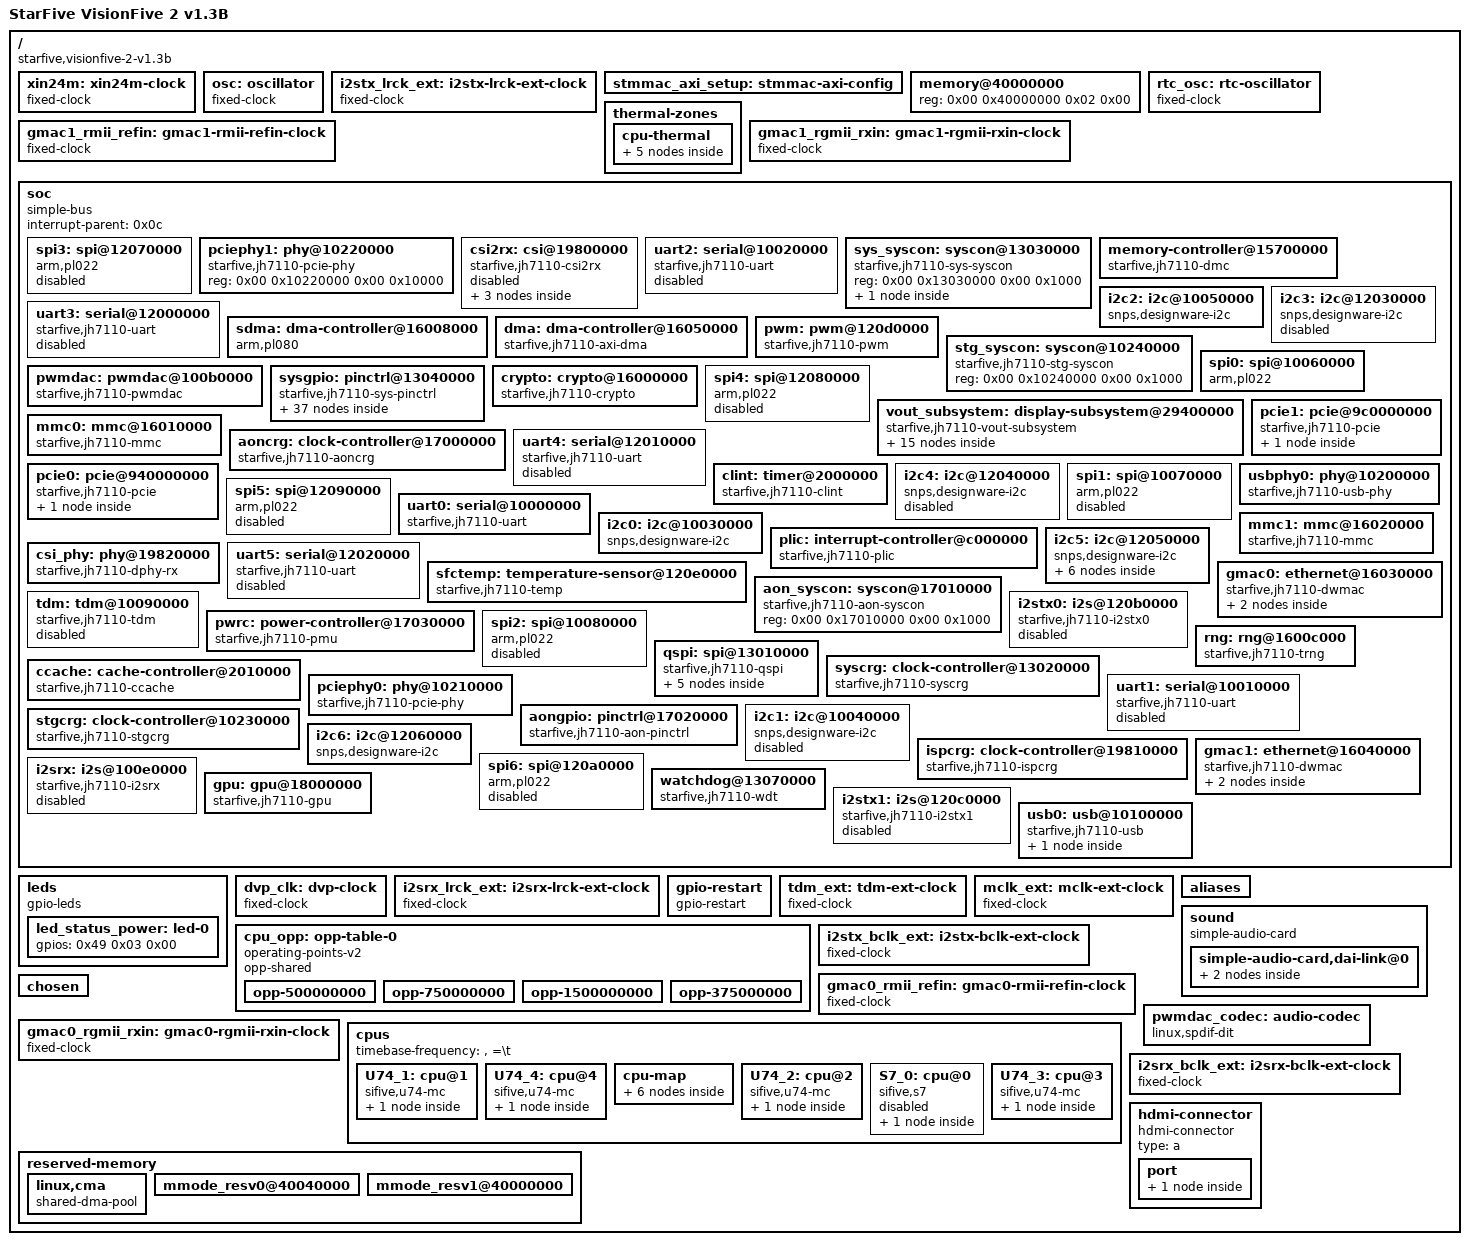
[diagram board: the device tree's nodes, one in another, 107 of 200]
/dts-v1/;

/ {
	#address-cells = <0x02>;
	model = "StarFive VisionFive 2 v1.3B";
	serial-number = "VF7110B1-2318-D008E000-18004700";
	#size-cells = <0x02>;
	compatible = "starfive,visionfive-2-v1.3b", "starfive,jh7110";

	xin24m: xin24m-clock {
		clock-output-names = "xin24m";
		#clock-cells = <0x00>;
		clock-frequency = <0x16e3600>;
		compatible = "fixed-clock";
		phandle = <0x42>;
	};

	osc: oscillator {
		clock-output-names = "osc";
		#clock-cells = <0x00>;
		clock-frequency = <0x16e3600>;
		compatible = "fixed-clock";
		bootph-pre-ram;
		phandle = <0x20>;
	};

	i2stx_lrck_ext: i2stx-lrck-ext-clock {
		clock-output-names = "i2stx_lrck_ext";
		#clock-cells = <0x00>;
		clock-frequency = <0x2ee00>;
		compatible = "fixed-clock";
		phandle = <0x24>;
	};

	stmmac_axi_setup: stmmac-axi-config {
		snps,lpi_en;
		snps,wr_osr_lmt = <0x0f>;
		phandle = <0x30>;
		snps,blen = <0x100 0x80 0x40 0x20 0x00 0x00 0x00>;
		snps,rd_osr_lmt = <0x0f>;
	};

	memory@40000000 {
		device_type = "memory";
		reg = <0x00 0x40000000 0x02 0x00>;
		bootph-pre-ram;
	};

	gmac1_rmii_refin: gmac1-rmii-refin-clock {
		clock-output-names = "gmac1_rmii_refin";
		#clock-cells = <0x00>;
		clock-frequency = <0x2faf080>;
		compatible = "fixed-clock";
		bootph-pre-ram;
		phandle = <0x26>;
	};

	rtc_osc: rtc-oscillator {
		clock-output-names = "rtc_osc";
		#clock-cells = <0x00>;
		clock-frequency = <0x8000>;
		compatible = "fixed-clock";
		phandle = <0x36>;
	};

	thermal-zones {

		cpu-thermal {
			polling-delay = <0x3a98>;
			polling-delay-passive = <0xfa>;
			thermal-sensors = <0x0a>;

			trips {

				cpu-crit {
					temperature = <0x186a0>;
					hysteresis = <0x7d0>;
					type = "critical";
				};

				cpu_alert0: cpu-alert0 {
					temperature = <0x14c08>;
					hysteresis = <0x7d0>;
					type = "passive";
					phandle = <0x0b>;
				};
			};

			cooling-maps {

				map0 {
					trip = <0x0b>;
					cooling-device = <0x06 0xffffffff 0xffffffff 0x07 0xffffffff 0xffffffff 0x08 0xffffffff 0xffffffff 0x09 0xffffffff 0xffffffff>;
				};
			};
		};
	};

	gmac1_rgmii_rxin: gmac1-rgmii-rxin-clock {
		clock-output-names = "gmac1_rgmii_rxin";
		#clock-cells = <0x00>;
		clock-frequency = <0x7735940>;
		compatible = "fixed-clock";
		bootph-pre-ram;
		phandle = <0x27>;
	};

	soc {
		#address-cells = <0x02>;
		#size-cells = <0x02>;
		interrupt-parent = <0x0c>;
		compatible = "simple-bus";
		ranges;

		spi3: spi@12070000 {
			arm,primecell-periphid = <0x41022>;
			#address-cells = <0x01>;
			num-cs = <0x01>;
			clock-names = "sspclk", "apb_pclk";
			resets = <0x03 0x48>;
			interrupts = <0x34>;
			clocks = <0x03 0x86 0x03 0x86>;
			#size-cells = <0x00>;
			compatible = "arm,pl022", "arm,primecell";
			status = "disabled";
			reg = <0x00 0x12070000 0x00 0x10000>;
			phandle = <0x65>;
		};

		pciephy1: phy@10220000 {
			#phy-cells = <0x00>;
			compatible = "starfive,jh7110-pcie-phy";
			reg = <0x00 0x10220000 0x00 0x10000>;
			phandle = <0x47>;
		};

		csi2rx: csi@19800000 {
			phy-names = "dphy";
			clock-names = "sys_clk", "p_clk", "pixel_if0_clk", "pixel_if1_clk", "pixel_if2_clk", "pixel_if3_clk";
			assigned-clocks = <0x38 0x07>;
			assigned-clock-rates = <0x11b3dc40>;
			resets = <0x38 0x09 0x38 0x04 0x38 0x05 0x38 0x06 0x38 0x07 0x38 0x08>;
			clocks = <0x38 0x07 0x38 0x06 0x38 0x08 0x38 0x09 0x38 0x0a 0x38 0x0b>;
			compatible = "starfive,jh7110-csi2rx", "cdns,csi2rx";
			status = "disabled";
			phys = <0x39>;
			reg = <0x00 0x19800000 0x00 0x10000>;
			phandle = <0x75>;
			reset-names = "sys", "reg_bank", "pixel_if0", "pixel_if1", "pixel_if2", "pixel_if3";

			ports {
				#address-cells = <0x01>;
				#size-cells = <0x00>;

				port@0 {
					reg = <0x00>;
				};

				port@1 {
					reg = <0x01>;
				};
			};
		};

		uart2: serial@10020000 {
			reg-io-width = <0x04>;
			clock-names = "baudclk", "apb_pclk";
			resets = <0x03 0x57 0x03 0x58>;
			interrupts = <0x22>;
			clocks = <0x03 0x96 0x03 0x95>;
			compatible = "starfive,jh7110-uart", "snps,dw-apb-uart";
			status = "disabled";
			reg = <0x00 0x10020000 0x00 0x10000>;
			phandle = <0x52>;
			reg-shift = <0x02>;
		};

		sys_syscon: syscon@13030000 {
			compatible = "starfive,jh7110-sys-syscon", "syscon", "simple-mfd";
			reg = <0x00 0x13030000 0x00 0x1000>;
			phandle = <0x1b>;

			pllclk: clock-controller {
				clocks = <0x20>;
				#clock-cells = <0x01>;
				compatible = "starfive,jh7110-pll";
				bootph-pre-ram;
				phandle = <0x28>;
			};
		};

		memory-controller@15700000 {
			clock-names = "pll";
			resets = <0x03 0x26 0x03 0x27 0x03 0x28>;
			clocks = <0x03 0x01>;
			compatible = "starfive,jh7110-dmc";
			reg = <0x00 0x15700000 0x00 0x10000 0x00 0x13000000 0x00 0x10000>;
			bootph-pre-ram;
			reset-names = "axi", "osc", "apb";
		};

		i2c2: i2c@10050000 {
			pinctrl-names = "default";
			#address-cells = <0x01>;
			i2c-sda-hold-time-ns = <0x12c>;
			pinctrl-0 = <0x14>;
			clock-names = "ref";
			i2c-scl-falling-time-ns = <0x1fe>;
			i2c-sda-falling-time-ns = <0x1fe>;
			resets = <0x03 0x4e>;
			interrupts = <0x25>;
			clocks = <0x03 0x8c>;
			#size-cells = <0x00>;
			clock-frequency = <0x186a0>;
			compatible = "snps,designware-i2c";
			status = "okay";
			reg = <0x00 0x10050000 0x00 0x10000>;
			phandle = <0x55>;
		};

		uart3: serial@12000000 {
			reg-io-width = <0x04>;
			clock-names = "baudclk", "apb_pclk";
			resets = <0x03 0x59 0x03 0x5a>;
			interrupts = <0x2d>;
			clocks = <0x03 0x98 0x03 0x97>;
			compatible = "starfive,jh7110-uart", "snps,dw-apb-uart";
			status = "disabled";
			reg = <0x00 0x12000000 0x00 0x10000>;
			phandle = <0x5d>;
			reg-shift = <0x02>;
		};

		sdma: dma-controller@16008000 {
			memcpy-bus-width = <0x20>;
			arm,primecell-periphid = <0x41080>;
			lli-bus-interface-ahb1;
			clock-names = "apb_pclk";
			resets = <0x1e 0x03>;
			interrupts = <0x1d>;
			clocks = <0x1e 0x0f>;
			memcpy-burst-size = <0x100>;
			compatible = "arm,pl080", "arm,primecell";
			mem-bus-interface-ahb1;
			reg = <0x00 0x16008000 0x00 0x4000>;
			phandle = <0x29>;
			#dma-cells = <0x02>;
		};

		i2c3: i2c@12030000 {
			#address-cells = <0x01>;
			clock-names = "ref";
			resets = <0x03 0x4f>;
			interrupts = <0x30>;
			clocks = <0x03 0x8d>;
			#size-cells = <0x00>;
			compatible = "snps,designware-i2c";
			status = "disabled";
			reg = <0x00 0x12030000 0x00 0x10000>;
			phandle = <0x60>;
		};

		dma: dma-controller@16050000 {
			snps,data-width = <0x03>;
			snps,priority = <0x00 0x01 0x02 0x03>;
			clock-names = "core-clk", "cfgr-clk";
			resets = <0x1e 0x05 0x1e 0x06>;
			interrupts = <0x49>;
			clocks = <0x1e 0x1b 0x1e 0x1c>;
			snps,axi-max-burst-len = <0x10>;
			snps,dma-masters = <0x01>;
			compatible = "starfive,jh7110-axi-dma";
			snps,block-size = <0x10000 0x10000 0x10000 0x10000>;
			reg = <0x00 0x16050000 0x00 0x10000>;
			phandle = <0x17>;
			dma-channels = <0x04>;
			#dma-cells = <0x01>;
		};

		pwm: pwm@120d0000 {
			pinctrl-names = "default";
			pinctrl-0 = <0x25>;
			resets = <0x03 0x6c>;
			clocks = <0x03 0x79>;
			#pwm-cells = <0x03>;
			compatible = "starfive,jh7110-pwm", "opencores,pwm-v1";
			status = "okay";
			reg = <0x00 0x120d0000 0x00 0x10000>;
			phandle = <0x6b>;
		};

		stg_syscon: syscon@10240000 {
			compatible = "starfive,jh7110-stg-syscon", "syscon";
			reg = <0x00 0x10240000 0x00 0x1000>;
			phandle = <0x1d>;
		};

		spi0: spi@10060000 {
			arm,primecell-periphid = <0x41022>;
			pinctrl-names = "default";
			#address-cells = <0x01>;
			num-cs = <0x01>;
			pinctrl-0 = <0x15>;
			clock-names = "sspclk", "apb_pclk";
			resets = <0x03 0x45>;
			interrupts = <0x26>;
			clocks = <0x03 0x83 0x03 0x83>;
			#size-cells = <0x00>;
			compatible = "arm,pl022", "arm,primecell";
			status = "okay";
			reg = <0x00 0x10060000 0x00 0x10000>;
			phandle = <0x56>;
		};

		pwmdac: pwmdac@100b0000 {
			pinctrl-names = "default";
			pinctrl-0 = <0x1c>;
			clock-names = "apb", "core";
			resets = <0x03 0x60>;
			clocks = <0x03 0x9d 0x03 0x9e>;
			dma-names = "tx";
			#sound-dai-cells = <0x00>;
			compatible = "starfive,jh7110-pwmdac";
			status = "okay";
			reg = <0x00 0x100b0000 0x00 0x1000>;
			phandle = <0x4b>;
			dmas = <0x17 0x16>;
		};

		sysgpio: pinctrl@13040000 {
			gpio-controller;
			resets = <0x03 0x02>;
			interrupts = <0x56>;
			clocks = <0x03 0x70>;
			compatible = "starfive,jh7110-sys-pinctrl";
			#interrupt-cells = <0x02>;
			reg = <0x00 0x13040000 0x00 0x10000>;
			phandle = <0x2e>;
			#gpio-cells = <0x02>;
			interrupt-controller;

			mmc1_pins: mmc1-0 {
				phandle = <0x2d>;

				clk-pins {
					input-schmitt-disable;
					input-disable;
					drive-strength = <0x0c>;
					pinmux = <0xff37000a>;
					slew-rate = <0x00>;
					bias-pull-up;
				};

				mmc-pins {
					drive-strength = <0x0c>;
					pinmux = <0x2c394c09 0x2d3a500b 0x2e3b540c 0x2f3c5807 0x303d5c08>;
					input-schmitt-enable;
					slew-rate = <0x00>;
					bias-pull-up;
					input-enable;
				};
			};

			i2c2_pins: i2c2-0 {
				phandle = <0x14>;

				i2c-pins {
					bias-disable;
					pinmux = <0x3b007803 0x3c007c02>;
					input-schmitt-enable;
					input-enable;
				};
			};

			i2c5_pins: i2c5-0 {
				bootph-pre-ram;
				phandle = <0x21>;

				i2c-pins {
					bias-disable;
					pinmux = <0x4f00a813 0x5000ac14>;
					input-schmitt-enable;
					bootph-pre-ram;
					input-enable;
				};
			};

			spi0_pins: spi0-0 {
				phandle = <0x15>;

				miso-pins {
					pinmux = <0x1c000435>;
					input-schmitt-enable;
					bias-pull-up;
					input-enable;
				};

				mosi-pins {
					input-schmitt-disable;
					input-disable;
					bias-disable;
					pinmux = <0xff200034>;
				};

				ss-pins {
					input-schmitt-disable;
					input-disable;
					bias-disable;
					pinmux = <0x1b1f0031>;
				};

				sck-pins {
					input-schmitt-disable;
					input-disable;
					bias-disable;
					pinmux = <0x1a1e0030>;
				};
			};

			mmc0_pins: mmc0-0 {
				phandle = <0x2a>;

				mmc-pins {
					drive-strength = <0x0c>;
					pinmux = <0x440 0x441 0x442 0x443 0x444 0x445 0x446 0x447 0x448 0x449>;
					bias-pull-up;
					input-enable;
				};

				rst-pins {
					input-schmitt-disable;
					input-disable;
					drive-strength = <0x0c>;
					pinmux = <0xff13003e>;
					slew-rate = <0x00>;
					bias-pull-up;
				};
			};

			hdmi_pins: hdmi-0 {
				phandle = <0x3f>;

				hdmi-cec-pins {
					pinmux = <0x50a080e>;
					bias-pull-up;
					input-enable;
				};

				hdmi-hpd-pins {
					bias-disable;
					pinmux = <0x800040f>;
					input-enable;
				};

				hdmi-scl-pins {
					pinmux = <0x60b0c00>;
					bias-pull-up;
					input-enable;
				};

				hdmi-sda-pins {
					pinmux = <0x70c1001>;
					bias-pull-up;
					input-enable;
				};
			};

			pwmdac_pins: pwmdac-0 {
				phandle = <0x1c>;

				pwmdac-pins {
					input-schmitt-disable;
					input-disable;
					drive-strength = <0x02>;
					bias-disable;
					pinmux = <0xff1c0021 0xff1d0022>;
					slew-rate = <0x00>;
				};
			};

			uart0_pins: uart0-0 {
				phandle = <0x12>;

				tx-pins {
					input-schmitt-disable;
					input-disable;
					drive-strength = <0x0c>;
					bias-disable;
					pinmux = <0xff140005>;
					slew-rate = <0x00>;
				};

				rx-pins {
					drive-strength = <0x02>;
					bias-disable;
					pinmux = <0xe000406>;
					input-schmitt-enable;
					slew-rate = <0x00>;
					input-enable;
				};
			};

			pcie1_pins: pcie1-0 {
				phandle = <0x48>;

				clkreq-pins {
					input-schmitt-disable;
					drive-strength = <0x02>;
					pinmux = <0xff00041d>;
					bias-pull-down;
					slew-rate = <0x00>;
					input-enable;
				};

				wake-pins {
					input-schmitt-disable;
					drive-strength = <0x02>;
					pinmux = <0xff000415>;
					slew-rate = <0x00>;
					bias-pull-up;
					input-enable;
				};
			};

			i2c0_pins: i2c0-0 {
				phandle = <0x13>;

				i2c-pins {
					bias-disable;
					pinmux = <0x9001439 0xa00183a>;
					input-schmitt-enable;
					input-enable;
				};
			};

			i2c6_pins: i2c6-0 {
				phandle = <0x22>;

				i2c-pins {
					bias-disable;
					pinmux = <0x5600b810 0x5700bc11>;
					input-schmitt-enable;
					input-enable;
				};
			};

			pwm_pins: pwm-0 {
				phandle = <0x25>;

				pwm-pins {
					input-schmitt-disable;
					input-disable;
					drive-strength = <0x0c>;
					bias-disable;
					pinmux = <0xff18242e 0xff19283b>;
					slew-rate = <0x00>;
				};
			};

			pcie0_pins: pcie0-0 {
				phandle = <0x45>;

				clkreq-pins {
					input-schmitt-disable;
					drive-strength = <0x02>;
					pinmux = <0xff00041b>;
					bias-pull-down;
					slew-rate = <0x00>;
					input-enable;
				};

				wake-pins {
					input-schmitt-disable;
					drive-strength = <0x02>;
					pinmux = <0xff000420>;
					slew-rate = <0x00>;
					bias-pull-up;
					input-enable;
				};
			};
		};

		crypto: crypto@16000000 {
			clock-names = "hclk", "ahb";
			resets = <0x1e 0x03>;
			interrupts = <0x1c>;
			clocks = <0x1e 0x0f 0x1e 0x10>;
			dma-names = "tx", "rx";
			compatible = "starfive,jh7110-crypto";
			reg = <0x00 0x16000000 0x00 0x4000>;
			phandle = <0x6e>;
			dmas = <0x29 0x01 0x02 0x29 0x00 0x02>;
		};

		spi4: spi@12080000 {
			arm,primecell-periphid = <0x41022>;
			#address-cells = <0x01>;
			num-cs = <0x01>;
			clock-names = "sspclk", "apb_pclk";
			resets = <0x03 0x49>;
			interrupts = <0x35>;
			clocks = <0x03 0x87 0x03 0x87>;
			#size-cells = <0x00>;
			compatible = "arm,pl022", "arm,primecell";
			status = "disabled";
			reg = <0x00 0x12080000 0x00 0x10000>;
			phandle = <0x66>;
		};

		vout_subsystem: display-subsystem@29400000 {
			power-domains = <0x37 0x04>;
			#address-cells = <0x02>;
			dma-noncoherent;
			resets = <0x03 0x1a>;
			clocks = <0x03 0x3c>;
			#size-cells = <0x02>;
			compatible = "starfive,jh7110-vout-subsystem";
			ranges;
			reg = <0x00 0x29400000 0x00 0x200000>;
			phandle = <0x76>;

			hdmi_subsystem: hdmi@29590000 {
				compatible = "starfive,jh7110-hdmi-subsystem";
				reg = <0x00 0x29590000 0x00 0x4000>;
				phandle = <0x7a>;

				hdmi_controller: controller {
					pinctrl-names = "default";
					pinctrl-0 = <0x3f>;
					clock-names = "pclk", "mclk", "bclk", "pixel";
					resets = <0x3b 0x09>;
					interrupts = <0x63>;
					clocks = <0x3b 0x11 0x3b 0x0f 0x3b 0x10 0x3c>;
					compatible = "starfive,jh7110-inno-hdmi-controller";
					status = "okay";
					starfive,vout-syscon = <0x3e>;
					phys = <0x3c>;
					phandle = <0x7b>;

					ports {
						#address-cells = <0x01>;
						#size-cells = <0x00>;

						port@0 {
							reg = <0x00>;

							hdmi_in: endpoint {
								remote-endpoint = <0x40>;
								phandle = <0x3d>;
							};
						};

						hdmi_out_port: port@1 {
							reg = <0x01>;
							phandle = <0x7c>;

							hdmi_out_con: endpoint {
								remote-endpoint = <0x41>;
								phandle = <0x4d>;
							};
						};
					};
				};

				hdmi_phy: phy {
					clocks = <0x42>;
					#clock-cells = <0x00>;
					#phy-cells = <0x00>;
					compatible = "starfive,jh7110-inno-hdmi-phy";
					phandle = <0x3c>;
				};
			};

			vout_syscon: syscon@295b0000 {
				compatible = "starfive,jh7110-vout-syscon", "syscon";
				reg = <0x00 0x295b0000 0x00 0x10000>;
				phandle = <0x3e>;
			};

			voutcrg: clock-controller@295c0000 {
				power-domains = <0x37 0x04>;
				#reset-cells = <0x01>;
				clock-names = "vout_src", "vout_top_ahb", "vout_top_axi", "vout_top_hdmitx0_mclk", "i2stx0_bclk", "hdmitx0_pixelclk";
				resets = <0x03 0x2b>;
				clocks = <0x03 0x3a 0x03 0x3d 0x03 0x3e 0x03 0x3f 0x03 0xa5 0x3c>;
				#clock-cells = <0x01>;
				compatible = "starfive,jh7110-voutcrg";
				status = "okay";
				reg = <0x00 0x295c0000 0x00 0x10000>;
				phandle = <0x3b>;
			};

			dc8200: display@29400000 {
				clock-names = "core", "axi", "ahb", "pix0", "pix1";
				assigned-clocks = <0x3b 0x07 0x3b 0x08>;
				assigned-clock-parents = <0x3c 0x3c>;
				resets = <0x3b 0x02 0x3b 0x00 0x3b 0x01>;
				interrupts = <0x5f>;
				clocks = <0x3b 0x05 0x3b 0x04 0x3b 0x06 0x3b 0x07 0x3b 0x08>;
				compatible = "starfive,jh7110-dc8200", "verisilicon,dc";
				status = "okay";
				reg = <0x00 0x29400000 0x00 0x2800>;
				phandle = <0x77>;
				reset-names = "core", "axi", "ahb";

				ports {
					#address-cells = <0x01>;
					#size-cells = <0x00>;

					dpu_port0: port@0 {
						#address-cells = <0x01>;
						#size-cells = <0x00>;
						reg = <0x00>;
						phandle = <0x78>;

						dpu_out_dpi0: endpoint@0 {
							remote-endpoint = <0x3d>;
							reg = <0x00>;
							phandle = <0x40>;
						};
					};

					dpu_port1: port@1 {
						reg = <0x01>;
						phandle = <0x79>;
					};
				};
			};
		};

		pcie1: pcie@9c0000000 {
			pinctrl-names = "default";
			#address-cells = <0x03>;
			bus-range = <0x00 0xff>;
			pinctrl-0 = <0x48>;
			clock-names = "noc", "tl", "axi_mst0", "apb";
			reg-names = "cfg", "apb";
			starfive,stg-syscon = <0x1d>;
			resets = <0x1e 0x11 0x1e 0x12 0x1e 0x13 0x1e 0x14 0x1e 0x15 0x1e 0x16>;
			interrupts = <0x39>;
			clocks = <0x03 0x60 0x1e 0x0d 0x1e 0x0b 0x1e 0x0c>;
			interrupt-map = <0x00 0x00 0x00 0x01 0x46 0x01 0x00 0x00 0x00 0x02 0x46 0x02 0x00 0x00 0x00 0x03 0x46 0x03 0x00 0x00 0x00 0x04 0x46 0x04>;
			#size-cells = <0x02>;
			perst-gpios = <0x2e 0x1c 0x01>;
			msi-controller;
			device_type = "pci";
			interrupt-map-mask = <0x00 0x00 0x00 0x07>;
			compatible = "starfive,jh7110-pcie";
			ranges = <0x82000000 0x00 0x38000000 0x00 0x38000000 0x00 0x8000000 0xc3000000 0x09 0x80000000 0x09 0x80000000 0x00 0x40000000>;
			#interrupt-cells = <0x01>;
			status = "okay";
			phys = <0x47>;
			reg = <0x09 0xc0000000 0x00 0x1000000 0x00 0x2c000000 0x00 0x100000>;
			linux,pci-domain = <0x01>;
			phandle = <0x7e>;
			reset-names = "mst0", "slv0", "slv", "brg", "core", "apb";

			pcie_intc1: interrupt-controller {
				#address-cells = <0x00>;
				#interrupt-cells = <0x01>;
				phandle = <0x46>;
				interrupt-controller;
			};
		};

		mmc0: mmc@16010000 {
			fifo-depth = <0x20>;
			pinctrl-names = "default";
			data-addr = <0x00>;
			pinctrl-0 = <0x2a>;
			clock-names = "biu", "ciu";
			vqmmc-supply = <0x2c>;
			assigned-clocks = <0x03 0x5d>;
			mmc-hs200-1_8v;
			bus-width = <0x08>;
			non-removable;
			assigned-clock-rates = <0x2faf080>;
			resets = <0x03 0x40>;
			interrupts = <0x4a>;
			clocks = <0x03 0x5b 0x03 0x5d>;
			vmmc-supply = <0x2b>;
			cap-mmc-hw-reset;
			mmc-ddr-1_8v;
			compatible = "starfive,jh7110-mmc";
			status = "okay";
			fifo-watermark-aligned;
			reg = <0x00 0x16010000 0x00 0x10000>;
			bootph-pre-ram;
			phandle = <0x70>;
			max-frequency = <0x5f5e100>;
			cap-mmc-highspeed;
			reset-names = "reset";
			starfive,sysreg = <0x1b 0x14 0x1a 0x7c000000>;
		};

		aoncrg: clock-controller@17000000 {
			#reset-cells = <0x01>;
			clock-names = "osc", "gmac0_rmii_refin", "gmac0_rgmii_rxin", "stg_axiahb", "apb_bus", "gmac0_gtxclk", "rtc_osc";
			clocks = <0x20 0x34 0x35 0x03 0x08 0x03 0x0b 0x03 0x6c 0x36>;
			#clock-cells = <0x01>;
			compatible = "starfive,jh7110-aoncrg";
			reg = <0x00 0x17000000 0x00 0x10000>;
			phandle = <0x2f>;
		};

		uart4: serial@12010000 {
			reg-io-width = <0x04>;
			clock-names = "baudclk", "apb_pclk";
			resets = <0x03 0x5b 0x03 0x5c>;
			interrupts = <0x2e>;
			clocks = <0x03 0x9a 0x03 0x99>;
			compatible = "starfive,jh7110-uart", "snps,dw-apb-uart";
			status = "disabled";
			reg = <0x00 0x12010000 0x00 0x10000>;
			phandle = <0x5e>;
			reg-shift = <0x02>;
		};

		pcie0: pcie@940000000 {
			pinctrl-names = "default";
			#address-cells = <0x03>;
			bus-range = <0x00 0xff>;
			pinctrl-0 = <0x45>;
			clock-names = "noc", "tl", "axi_mst0", "apb";
			reg-names = "cfg", "apb";
			starfive,stg-syscon = <0x1d>;
			resets = <0x1e 0x0b 0x1e 0x0c 0x1e 0x0d 0x1e 0x0e 0x1e 0x0f 0x1e 0x10>;
			interrupts = <0x38>;
			clocks = <0x03 0x60 0x1e 0x0a 0x1e 0x08 0x1e 0x09>;
			interrupt-map = <0x00 0x00 0x00 0x01 0x43 0x01 0x00 0x00 0x00 0x02 0x43 0x02 0x00 0x00 0x00 0x03 0x43 0x03 0x00 0x00 0x00 0x04 0x43 0x04>;
			#size-cells = <0x02>;
			perst-gpios = <0x2e 0x1a 0x01>;
			msi-controller;
			device_type = "pci";
			interrupt-map-mask = <0x00 0x00 0x00 0x07>;
			compatible = "starfive,jh7110-pcie";
			ranges = <0x82000000 0x00 0x30000000 0x00 0x30000000 0x00 0x8000000 0xc3000000 0x09 0x00 0x09 0x00 0x00 0x40000000>;
			#interrupt-cells = <0x01>;
			status = "okay";
			phys = <0x44>;
			reg = <0x09 0x40000000 0x00 0x1000000 0x00 0x2b000000 0x00 0x100000>;
			linux,pci-domain = <0x00>;
			phandle = <0x7d>;
			reset-names = "mst0", "slv0", "slv", "brg", "core", "apb";

			pcie_intc0: interrupt-controller {
				#address-cells = <0x00>;
				#interrupt-cells = <0x01>;
				phandle = <0x43>;
				interrupt-controller;
			};
		};

		clint: timer@2000000 {
			interrupts-extended = <0x0d 0x03 0x0d 0x07 0x0e 0x03 0x0e 0x07 0x0f 0x03 0x0f 0x07 0x10 0x03 0x10 0x07 0x11 0x03 0x11 0x07>;
			compatible = "starfive,jh7110-clint", "sifive,clint0";
			reg = <0x00 0x2000000 0x00 0x10000>;
			bootph-pre-ram;
			phandle = <0x4f>;
		};

		i2c4: i2c@12040000 {
			#address-cells = <0x01>;
			clock-names = "ref";
			resets = <0x03 0x50>;
			interrupts = <0x31>;
			clocks = <0x03 0x8e>;
			#size-cells = <0x00>;
			compatible = "snps,designware-i2c";
			status = "disabled";
			reg = <0x00 0x12040000 0x00 0x10000>;
			phandle = <0x61>;
		};

		spi1: spi@10070000 {
			arm,primecell-periphid = <0x41022>;
			#address-cells = <0x01>;
			num-cs = <0x01>;
			clock-names = "sspclk", "apb_pclk";
			resets = <0x03 0x46>;
			interrupts = <0x27>;
			clocks = <0x03 0x84 0x03 0x84>;
			#size-cells = <0x00>;
			compatible = "arm,pl022", "arm,primecell";
			status = "disabled";
			reg = <0x00 0x10070000 0x00 0x10000>;
			phandle = <0x57>;
		};

		usbphy0: phy@10200000 {
			clock-names = "125m", "app_125m";
			clocks = <0x03 0x5f 0x1e 0x06>;
			#phy-cells = <0x00>;
			compatible = "starfive,jh7110-usb-phy";
			reg = <0x00 0x10200000 0x00 0x10000>;
			phandle = <0x1f>;
		};

		spi5: spi@12090000 {
			arm,primecell-periphid = <0x41022>;
			#address-cells = <0x01>;
			num-cs = <0x01>;
			clock-names = "sspclk", "apb_pclk";
			resets = <0x03 0x4a>;
			interrupts = <0x36>;
			clocks = <0x03 0x88 0x03 0x88>;
			#size-cells = <0x00>;
			compatible = "arm,pl022", "arm,primecell";
			status = "disabled";
			reg = <0x00 0x12090000 0x00 0x10000>;
			phandle = <0x67>;
		};

		uart0: serial@10000000 {
			reg-io-width = <0x04>;
			pinctrl-names = "default";
			pinctrl-0 = <0x12>;
			clock-names = "baudclk", "apb_pclk";
			resets = <0x03 0x53 0x03 0x54>;
			interrupts = <0x20>;
			clocks = <0x03 0x92 0x03 0x91>;
			compatible = "starfive,jh7110-uart", "snps,dw-apb-uart";
			status = "okay";
			reg = <0x00 0x10000000 0x00 0x10000>;
			bootph-pre-ram;
			phandle = <0x50>;
			reg-shift = <0x02>;
		};

		i2c0: i2c@10030000 {
			pinctrl-names = "default";
			#address-cells = <0x01>;
			i2c-sda-hold-time-ns = <0x12c>;
			pinctrl-0 = <0x13>;
			clock-names = "ref";
			i2c-scl-falling-time-ns = <0x1fe>;
			i2c-sda-falling-time-ns = <0x1fe>;
			resets = <0x03 0x4c>;
			interrupts = <0x23>;
			clocks = <0x03 0x8a>;
			#size-cells = <0x00>;
			clock-frequency = <0x186a0>;
			compatible = "snps,designware-i2c";
			status = "okay";
			reg = <0x00 0x10030000 0x00 0x10000>;
			phandle = <0x53>;
		};

		mmc1: mmc@16020000 {
			fifo-depth = <0x20>;
			pinctrl-names = "default";
			data-addr = <0x00>;
			pinctrl-0 = <0x2d>;
			clock-names = "biu", "ciu";
			cap-sd-highspeed;
			assigned-clocks = <0x03 0x5e>;
			bus-width = <0x04>;
			assigned-clock-rates = <0x2faf080>;
			resets = <0x03 0x41>;
			interrupts = <0x4b>;
			clocks = <0x03 0x5c 0x03 0x5e>;
			compatible = "starfive,jh7110-mmc";
			status = "okay";
			disable-wp;
			fifo-watermark-aligned;
			reg = <0x00 0x16020000 0x00 0x10000>;
			bootph-pre-ram;
			phandle = <0x71>;
			max-frequency = <0x5f5e100>;
			reset-names = "reset";
			cd-gpios = <0x2e 0x29 0x01>;
			starfive,sysreg = <0x1b 0x9c 0x01 0x3e>;
		};

		plic: interrupt-controller@c000000 {
			#address-cells = <0x00>;
			interrupts-extended = <0x0d 0x0b 0x0e 0x0b 0x0e 0x09 0x0f 0x0b 0x0f 0x09 0x10 0x0b 0x10 0x09 0x11 0x0b 0x11 0x09>;
			compatible = "starfive,jh7110-plic", "sifive,plic-1.0.0";
			#interrupt-cells = <0x01>;
			reg = <0x00 0xc000000 0x00 0x4000000>;
			phandle = <0x0c>;
			riscv,ndev = <0x88>;
			interrupt-controller;
		};

		csi_phy: phy@19820000 {
			power-domains = <0x31 0x01>;
			clock-names = "cfg", "ref", "tx";
			resets = <0x38 0x02 0x38 0x03>;
			clocks = <0x38 0x03 0x38 0x04 0x38 0x05>;
			#phy-cells = <0x00>;
			compatible = "starfive,jh7110-dphy-rx";
			reg = <0x00 0x19820000 0x00 0x10000>;
			phandle = <0x39>;
		};

		uart5: serial@12020000 {
			reg-io-width = <0x04>;
			clock-names = "baudclk", "apb_pclk";
			resets = <0x03 0x5d 0x03 0x5e>;
			interrupts = <0x2f>;
			clocks = <0x03 0x9c 0x03 0x9b>;
			compatible = "starfive,jh7110-uart", "snps,dw-apb-uart";
			status = "disabled";
			reg = <0x00 0x12020000 0x00 0x10000>;
			phandle = <0x5f>;
			reg-shift = <0x02>;
		};

		sfctemp: temperature-sensor@120e0000 {
			clock-names = "sense", "bus";
			resets = <0x03 0x7c 0x03 0x7b>;
			clocks = <0x03 0x82 0x03 0x81>;
			#thermal-sensor-cells = <0x00>;
			compatible = "starfive,jh7110-temp";
			reg = <0x00 0x120e0000 0x00 0x10000>;
			phandle = <0x0a>;
			reset-names = "sense", "bus";
		};

		i2c5: i2c@12050000 {
			pinctrl-names = "default";
			#address-cells = <0x01>;
			i2c-sda-hold-time-ns = <0x12c>;
			pinctrl-0 = <0x21>;
			clock-names = "ref";
			i2c-scl-falling-time-ns = <0x1fe>;
			i2c-sda-falling-time-ns = <0x1fe>;
			resets = <0x03 0x51>;
			interrupts = <0x32>;
			clocks = <0x03 0x8f>;
			#size-cells = <0x00>;
			clock-frequency = <0x186a0>;
			compatible = "snps,designware-i2c";
			status = "okay";
			reg = <0x00 0x12050000 0x00 0x10000>;
			phandle = <0x62>;

			eeprom@50 {
				compatible = "atmel,24c04";
				pagesize = <0x10>;
				reg = <0x50>;
				bootph-pre-ram;
			};

			axp15060: pmic@36 {
				compatible = "x-powers,axp15060";
				#interrupt-cells = <0x01>;
				reg = <0x36>;
				phandle = <0x63>;
				interrupt-controller;

				regulators {

					vcc_3v3: dcdc1 {
						regulator-max-microvolt = <0x325aa0>;
						regulator-boot-on;
						regulator-always-on;
						regulator-min-microvolt = <0x325aa0>;
						regulator-name = "vcc_3v3";
						phandle = <0x2b>;
					};

					emmc_vdd: aldo4 {
						regulator-max-microvolt = <0x325aa0>;
						regulator-boot-on;
						regulator-always-on;
						regulator-min-microvolt = <0x1b7740>;
						regulator-name = "emmc_vdd";
						phandle = <0x2c>;
					};

					vdd_cpu: dcdc2 {
						regulator-max-microvolt = <0x177fa0>;
						regulator-always-on;
						regulator-min-microvolt = <0x7a120>;
						regulator-name = "vdd_cpu";
						phandle = <0x04>;
					};
				};
			};
		};

		gmac0: ethernet@16030000 {
			snps,multicast-filter-bins = <0x40>;
			phy-mode = "rgmii-id";
			snps,txpbl = <0x10>;
			clock-names = "stmmaceth", "pclk", "ptp_ref", "tx", "gtx";
			assigned-clocks = <0x2f 0x05>;
			assigned-clock-parents = <0x2f 0x04>;
			local-mac-address = [6c cf 39 00 b7 46];
			snps,fixed-burst;
			resets = <0x2f 0x00 0x2f 0x01>;
			interrupts = <0x07 0x06 0x05>;
			clocks = <0x2f 0x03 0x2f 0x02 0x03 0x6d 0x2f 0x06 0x03 0x6f>;
			snps,no-pbl-x8;
			snps,tso;
			starfive,syscon = <0x31 0x0c 0x12>;
			snps,rxpbl = <0x10>;
			compatible = "starfive,jh7110-dwmac", "snps,dwmac-5.20";
			status = "okay";
			tx-fifo-depth = <0x800>;
			interrupt-names = "macirq", "eth_wake_irq", "eth_lpi";
			snps,force_thresh_dma_mode;
			rx-fifo-depth = <0x800>;
			reg = <0x00 0x16030000 0x00 0x10000>;
			phandle = <0x72>;
			phy-handle = <0x32>;
			reset-names = "stmmaceth", "ahb";
			snps,axi-config = <0x30>;
			starfive,tx-use-rgmii-clk;
			snps,perfect-filter-entries = <0x100>;

			mdio {
				#address-cells = <0x01>;
				#size-cells = <0x00>;
				compatible = "snps,dwmac-mdio";

				phy0: ethernet-phy@0 {
					rx-internal-delay-ps = <0x5dc>;
					motorcomm,rx-clk-drv-microamp = <0xf82>;
					motorcomm,rx-data-drv-microamp = <0xb5e>;
					motorcomm,tx-clk-100-inverted;
					reg = <0x00>;
					motorcomm,tx-clk-1000-inverted;
					phandle = <0x32>;
					tx-internal-delay-ps = <0x5dc>;
					motorcomm,tx-clk-adj-enabled;
				};
			};
		};

		aon_syscon: syscon@17010000 {
			#power-domain-cells = <0x01>;
			compatible = "starfive,jh7110-aon-syscon", "syscon";
			reg = <0x00 0x17010000 0x00 0x1000>;
			phandle = <0x31>;
		};

		tdm: tdm@10090000 {
			clock-names = "tdm_ahb", "tdm_apb", "tdm_internal", "tdm", "mclk_inner", "tdm_ext";
			resets = <0x03 0x69 0x03 0x6b 0x03 0x6a>;
			clocks = <0x03 0xb8 0x03 0xb9 0x03 0xba 0x03 0xbb 0x03 0x11 0x16>;
			dma-names = "rx", "tx";
			#sound-dai-cells = <0x00>;
			compatible = "starfive,jh7110-tdm";
			status = "disabled";
			reg = <0x00 0x10090000 0x00 0x1000>;
			phandle = <0x59>;
			dmas = <0x17 0x14 0x17 0x15>;
		};

		pwrc: power-controller@17030000 {
			interrupts = <0x6f>;
			#power-domain-cells = <0x01>;
			compatible = "starfive,jh7110-pmu";
			reg = <0x00 0x17030000 0x00 0x10000>;
			phandle = <0x37>;
		};

		i2stx0: i2s@120b0000 {
			clock-names = "i2sclk", "apb", "mclk", "mclk_inner", "mclk_ext";
			resets = <0x03 0x65 0x03 0x66>;
			clocks = <0x03 0xa2 0x03 0xa1 0x03 0x12 0x03 0x11 0x18>;
			dma-names = "tx";
			#sound-dai-cells = <0x00>;
			compatible = "starfive,jh7110-i2stx0";
			status = "disabled";
			reg = <0x00 0x120b0000 0x00 0x1000>;
			phandle = <0x69>;
			dmas = <0x17 0x2f>;
		};

		spi2: spi@10080000 {
			arm,primecell-periphid = <0x41022>;
			#address-cells = <0x01>;
			num-cs = <0x01>;
			clock-names = "sspclk", "apb_pclk";
			resets = <0x03 0x47>;
			interrupts = <0x28>;
			clocks = <0x03 0x85 0x03 0x85>;
			#size-cells = <0x00>;
			compatible = "arm,pl022", "arm,primecell";
			status = "disabled";
			reg = <0x00 0x10080000 0x00 0x10000>;
			phandle = <0x58>;
		};

		rng: rng@1600c000 {
			clock-names = "hclk", "ahb";
			resets = <0x1e 0x03>;
			interrupts = <0x1e>;
			clocks = <0x1e 0x0f 0x1e 0x10>;
			compatible = "starfive,jh7110-trng";
			reg = <0x00 0x1600c000 0x00 0x4000>;
			phandle = <0x6f>;
		};

		qspi: spi@13010000 {
			#address-cells = <0x01>;
			clock-names = "ref", "ahb", "apb";
			resets = <0x03 0x3e 0x03 0x3d 0x03 0x3f>;
			interrupts = <0x19>;
			clocks = <0x03 0x5a 0x03 0x57 0x03 0x58>;
			cdns,fifo-width = <0x04>;
			#size-cells = <0x00>;
			cdns,trigger-address = <0x00>;
			compatible = "starfive,jh7110-qspi", "cdns,qspi-nor";
			status = "okay";
			reg = <0x00 0x13010000 0x00 0x10000 0x00 0x21000000 0x00 0x400000>;
			phandle = <0x6c>;
			reset-names = "qspi", "qspi-ocp", "rstc_ref";
			cdns,fifo-depth = <0x100>;

			nor_flash: flash@0 {
				cdns,tshsl-ns = <0x01>;
				spi-max-frequency = <0x5f5e100>;
				cdns,tsd2d-ns = <0x01>;
				cdns,read-delay = <0x02>;
				cdns,tslch-ns = <0x01>;
				compatible = "jedec,spi-nor";
				reg = <0x00>;
				bootph-pre-ram;
				phandle = <0x6d>;
				cdns,tchsh-ns = <0x01>;

				partitions {
					#address-cells = <0x01>;
					#size-cells = <0x01>;
					compatible = "fixed-partitions";

					uboot-env@f0000 {
						reg = <0xf0000 0x10000>;
					};

					spl@0 {
						reg = <0x00 0xf0000>;
					};

					uboot@100000 {
						reg = <0x100000 0xf00000>;
					};
				};
			};
		};

		syscrg: clock-controller@13020000 {
			#reset-cells = <0x01>;
			clock-names = "osc", "gmac1_rmii_refin", "gmac1_rgmii_rxin", "i2stx_bclk_ext", "i2stx_lrck_ext", "i2srx_bclk_ext", "i2srx_lrck_ext", "tdm_ext", "mclk_ext", "pll0_out", "pll1_out", "pll2_out";
			assigned-clocks = <0x03 0x00 0x03 0x05 0x03 0x04 0x03 0x5a 0x03 0x01 0x28 0x00>;
			assigned-clock-parents = <0x28 0x00 0x28 0x02 0x28 0x02 0x03 0x59>;
			assigned-clock-rates = <0x00 0x00 0x00 0x00 0x1dcd6500 0x59682f00>;
			clocks = <0x20 0x26 0x27 0x23 0x24 0x19 0x1a 0x16 0x18 0x28 0x00 0x28 0x01 0x28 0x02>;
			#clock-cells = <0x01>;
			compatible = "starfive,jh7110-syscrg";
			reg = <0x00 0x13020000 0x00 0x10000>;
			bootph-pre-ram;
			phandle = <0x03>;
		};

		ccache: cache-controller@2010000 {
			cache-size = <0x200000>;
			cache-level = <0x02>;
			cache-sets = <0x800>;
			interrupts = <0x01 0x03 0x04 0x02>;
			cache-unified;
			compatible = "starfive,jh7110-ccache", "sifive,ccache0", "cache";
			reg = <0x00 0x2010000 0x00 0x4000>;
			phandle = <0x01>;
			cache-block-size = <0x40>;
		};

		pciephy0: phy@10210000 {
			starfive,sys-syscon = <0x1b 0x18>;
			starfive,stg-syscon = <0x1d 0x148 0x1f4>;
			#phy-cells = <0x00>;
			compatible = "starfive,jh7110-pcie-phy";
			reg = <0x00 0x10210000 0x00 0x10000>;
			phandle = <0x44>;
		};

		uart1: serial@10010000 {
			reg-io-width = <0x04>;
			clock-names = "baudclk", "apb_pclk";
			resets = <0x03 0x55 0x03 0x56>;
			interrupts = <0x21>;
			clocks = <0x03 0x94 0x03 0x93>;
			compatible = "starfive,jh7110-uart", "snps,dw-apb-uart";
			status = "disabled";
			reg = <0x00 0x10010000 0x00 0x10000>;
			phandle = <0x51>;
			reg-shift = <0x02>;
		};

		aongpio: pinctrl@17020000 {
			gpio-controller;
			resets = <0x2f 0x02>;
			interrupts = <0x55>;
			compatible = "starfive,jh7110-aon-pinctrl";
			#interrupt-cells = <0x02>;
			reg = <0x00 0x17020000 0x00 0x10000>;
			phandle = <0x49>;
			#gpio-cells = <0x02>;
			interrupt-controller;
		};

		i2c1: i2c@10040000 {
			#address-cells = <0x01>;
			clock-names = "ref";
			resets = <0x03 0x4d>;
			interrupts = <0x24>;
			clocks = <0x03 0x8b>;
			#size-cells = <0x00>;
			compatible = "snps,designware-i2c";
			status = "disabled";
			reg = <0x00 0x10040000 0x00 0x10000>;
			phandle = <0x54>;
		};

		stgcrg: clock-controller@10230000 {
			#reset-cells = <0x01>;
			clock-names = "osc", "hifi4_core", "stg_axiahb", "usb_125m", "cpu_bus", "hifi4_axi", "nocstg_bus", "apb_bus";
			clocks = <0x20 0x03 0x36 0x03 0x08 0x03 0x5f 0x03 0x02 0x03 0x37 0x03 0x06 0x03 0x0b>;
			#clock-cells = <0x01>;
			compatible = "starfive,jh7110-stgcrg";
			reg = <0x00 0x10230000 0x00 0x10000>;
			phandle = <0x1e>;
		};

		ispcrg: clock-controller@19810000 {
			power-domains = <0x37 0x05>;
			#reset-cells = <0x01>;
			clock-names = "isp_top_core", "isp_top_axi", "noc_bus_isp_axi", "dvp_clk";
			resets = <0x03 0x29 0x03 0x2a 0x03 0x1c>;
			clocks = <0x03 0x33 0x03 0x34 0x03 0x35 0x3a>;
			#clock-cells = <0x01>;
			compatible = "starfive,jh7110-ispcrg";
			reg = <0x00 0x19810000 0x00 0x10000>;
			phandle = <0x38>;
		};

		i2c6: i2c@12060000 {
			pinctrl-names = "default";
			#address-cells = <0x01>;
			i2c-sda-hold-time-ns = <0x12c>;
			pinctrl-0 = <0x22>;
			clock-names = "ref";
			i2c-scl-falling-time-ns = <0x1fe>;
			i2c-sda-falling-time-ns = <0x1fe>;
			resets = <0x03 0x52>;
			interrupts = <0x33>;
			clocks = <0x03 0x90>;
			#size-cells = <0x00>;
			clock-frequency = <0x186a0>;
			compatible = "snps,designware-i2c";
			status = "okay";
			reg = <0x00 0x12060000 0x00 0x10000>;
			phandle = <0x64>;
		};

		gmac1: ethernet@16040000 {
			snps,multicast-filter-bins = <0x40>;
			phy-mode = "rgmii-id";
			snps,txpbl = <0x10>;
			clock-names = "stmmaceth", "pclk", "ptp_ref", "tx", "gtx";
			assigned-clocks = <0x03 0x69>;
			assigned-clock-parents = <0x03 0x65>;
			local-mac-address = [6c cf 39 00 b7 47];
			snps,fixed-burst;
			resets = <0x03 0x42 0x03 0x43>;
			interrupts = <0x4e 0x4d 0x4c>;
			clocks = <0x03 0x62 0x03 0x61 0x03 0x66 0x03 0x6a 0x03 0x6b>;
			snps,no-pbl-x8;
			snps,tso;
			starfive,syscon = <0x1b 0x90 0x02>;
			snps,rxpbl = <0x10>;
			compatible = "starfive,jh7110-dwmac", "snps,dwmac-5.20";
			status = "okay";
			tx-fifo-depth = <0x800>;
			interrupt-names = "macirq", "eth_wake_irq", "eth_lpi";
			snps,force_thresh_dma_mode;
			rx-fifo-depth = <0x800>;
			reg = <0x00 0x16040000 0x00 0x10000>;
			phandle = <0x73>;
			phy-handle = <0x33>;
			reset-names = "stmmaceth", "ahb";
			snps,axi-config = <0x30>;
			starfive,tx-use-rgmii-clk;
			snps,perfect-filter-entries = <0x100>;

			mdio {
				#address-cells = <0x01>;
				#size-cells = <0x00>;
				compatible = "snps,dwmac-mdio";

				phy1: ethernet-phy@1 {
					rx-internal-delay-ps = <0x12c>;
					motorcomm,rx-clk-drv-microamp = <0xf82>;
					motorcomm,rx-data-drv-microamp = <0xb5e>;
					motorcomm,tx-clk-100-inverted;
					reg = <0x00>;
					phandle = <0x33>;
					tx-internal-delay-ps = <0x00>;
					motorcomm,tx-clk-adj-enabled;
				};
			};
		};

		spi6: spi@120a0000 {
			arm,primecell-periphid = <0x41022>;
			#address-cells = <0x01>;
			num-cs = <0x01>;
			clock-names = "sspclk", "apb_pclk";
			resets = <0x03 0x4b>;
			interrupts = <0x37>;
			clocks = <0x03 0x89 0x03 0x89>;
			#size-cells = <0x00>;
			compatible = "arm,pl022", "arm,primecell";
			status = "disabled";
			reg = <0x00 0x120a0000 0x00 0x10000>;
			phandle = <0x68>;
		};

		i2srx: i2s@100e0000 {
			clock-names = "i2sclk", "apb", "mclk", "mclk_inner", "mclk_ext", "bclk", "lrck", "bclk_ext", "lrck_ext";
			resets = <0x03 0x63 0x03 0x64>;
			clocks = <0x03 0xb0 0x03 0xaf 0x03 0x12 0x03 0x11 0x18 0x03 0xb3 0x03 0xb5 0x19 0x1a>;
			dma-names = "tx", "rx";
			#sound-dai-cells = <0x00>;
			starfive,syscon = <0x1b 0x18 0x02>;
			compatible = "starfive,jh7110-i2srx";
			status = "disabled";
			reg = <0x00 0x100e0000 0x00 0x1000>;
			phandle = <0x5a>;
			dmas = <0x00 0x17 0x18>;
		};

		watchdog@13070000 {
			clock-names = "apb", "core";
			resets = <0x03 0x6d 0x03 0x6e>;
			clocks = <0x03 0x7a 0x03 0x7b>;
			compatible = "starfive,jh7110-wdt";
			reg = <0x00 0x13070000 0x00 0x10000>;
		};

		gpu: gpu@18000000 {
			power-domains = <0x37 0x02>;
			dma-noncoherent;
			clock-names = "core", "sys", "mem", "core_clk", "apb", "rtc";
			resets = <0x03 0x15 0x03 0x16>;
			interrupts = <0x52>;
			clocks = <0x03 0x2d 0x03 0x2f 0x03 0x32 0x03 0x2e 0x03 0x30 0x03 0x31>;
			compatible = "starfive,jh7110-gpu", "img,img-bxe-4-32", "img,img-rogue";
			status = "okay";
			reg = <0x00 0x18000000 0x00 0x100000 0x00 0x130c000 0x00 0x10000>;
			phandle = <0x74>;
			reset-names = "apb", "doma";
		};

		i2stx1: i2s@120c0000 {
			clock-names = "i2sclk", "apb", "mclk", "mclk_inner", "mclk_ext", "bclk", "lrck", "bclk_ext", "lrck_ext";
			resets = <0x03 0x67 0x03 0x68>;
			clocks = <0x03 0xa9 0x03 0xa8 0x03 0x12 0x03 0x11 0x18 0x03 0xac 0x03 0xae 0x23 0x24>;
			dma-names = "tx";
			#sound-dai-cells = <0x00>;
			compatible = "starfive,jh7110-i2stx1";
			status = "disabled";
			reg = <0x00 0x120c0000 0x00 0x1000>;
			phandle = <0x6a>;
			dmas = <0x17 0x30>;
		};

		usb0: usb@10100000 {
			#address-cells = <0x01>;
			clock-names = "lpm", "stb", "apb", "axi", "utmi_apb";
			starfive,stg-syscon = <0x1d 0x04>;
			resets = <0x1e 0x0a 0x1e 0x08 0x1e 0x07 0x1e 0x09>;
			clocks = <0x1e 0x04 0x1e 0x05 0x1e 0x01 0x1e 0x03 0x1e 0x02>;
			#size-cells = <0x01>;
			compatible = "starfive,jh7110-usb";
			ranges = <0x00 0x00 0x10100000 0x100000>;
			status = "okay";
			phandle = <0x5b>;
			dr_mode = "peripheral";
			reset-names = "pwrup", "apb", "axi", "utmi_apb";

			usb_cdns3: usb@0 {
				phy-names = "cdns3,usb2-phy";
				reg-names = "otg", "xhci", "dev";
				interrupts = <0x64 0x6c 0x6e>;
				compatible = "cdns,usb3";
				interrupt-names = "host", "peripheral", "otg";
				phys = <0x1f>;
				reg = <0x00 0x10000 0x10000 0x10000 0x20000 0x10000>;
				phandle = <0x5c>;
			};
		};
	};

	leds {
		compatible = "gpio-leds";

		led_status_power: led-0 {
			phandle = <0x7f>;
			gpios = <0x49 0x03 0x00>;
		};
	};

	dvp_clk: dvp-clock {
		clock-output-names = "dvp_clk";
		#clock-cells = <0x00>;
		clock-frequency = <0x46cf710>;
		compatible = "fixed-clock";
		phandle = <0x3a>;
	};

	i2srx_lrck_ext: i2srx-lrck-ext-clock {
		clock-output-names = "i2srx_lrck_ext";
		#clock-cells = <0x00>;
		clock-frequency = <0x2ee00>;
		compatible = "fixed-clock";
		phandle = <0x1a>;
	};

	gpio-restart {
		priority = <0xe0>;
		compatible = "gpio-restart";
		gpios = <0x2e 0x23 0x00>;
	};

	tdm_ext: tdm-ext-clock {
		clock-output-names = "tdm_ext";
		#clock-cells = <0x00>;
		clock-frequency = <0x2ee0000>;
		compatible = "fixed-clock";
		phandle = <0x16>;
	};

	mclk_ext: mclk-ext-clock {
		clock-output-names = "mclk_ext";
		#clock-cells = <0x00>;
		clock-frequency = <0xbb8000>;
		compatible = "fixed-clock";
		phandle = <0x18>;
	};

	cpu_opp: opp-table-0 {
		opp-shared;
		compatible = "operating-points-v2";
		phandle = <0x02>;

		opp-500000000 {
			opp-microvolt = "", "\f5";
			opp-hz = <0x00 0x1dcd6500>;
		};

		opp-750000000 {
			opp-microvolt = "", "\f5";
			opp-hz = <0x00 0x2cb41780>;
		};

		opp-1500000000 {
			opp-microvolt = <0xfde80>;
			opp-hz = <0x00 0x59682f00>;
		};

		opp-375000000 {
			opp-microvolt = "", "\f5";
			opp-hz = <0x00 0x165a0bc0>;
		};
	};

	aliases {
		ethernet0 = "/soc/ethernet@16030000";
		mmc1 = "/soc/mmc@16020000";
		i2c6 = "/soc/i2c@12060000";
		ethernet1 = "/soc/ethernet@16040000";
		i2c2 = "/soc/i2c@10050000";
		i2c0 = "/soc/i2c@10030000";
		mmc0 = "/soc/mmc@16010000";
		i2c5 = "/soc/i2c@12050000";
		serial0 = "/soc/serial@10000000";
	};

	sound {
		simple-audio-card,name = "StarFive-PWMDAC-Sound-Card";
		#address-cells = <0x01>;
		#size-cells = <0x00>;
		compatible = "simple-audio-card";

		simple-audio-card,dai-link@0 {
			format = "left_j";
			frame-master = <0x4a>;
			bitclock-master = <0x4a>;
			reg = <0x00>;

			sndcpu0: cpu {
				phandle = <0x4a>;
				sound-dai = <0x4b>;
			};

			codec {
				sound-dai = <0x4c>;
			};
		};
	};

	i2stx_bclk_ext: i2stx-bclk-ext-clock {
		clock-output-names = "i2stx_bclk_ext";
		#clock-cells = <0x00>;
		clock-frequency = <0xbb8000>;
		compatible = "fixed-clock";
		phandle = <0x23>;
	};

	gmac0_rmii_refin: gmac0-rmii-refin-clock {
		clock-output-names = "gmac0_rmii_refin";
		#clock-cells = <0x00>;
		clock-frequency = <0x2faf080>;
		compatible = "fixed-clock";
		phandle = <0x34>;
	};

	chosen {
		linux,uefi-mmap-size = <0x4d8>;
		u-boot,version = "2025.01-3";
		bootargs = "BOOT_IMAGE=/boot/vmlinuz-7.3.0-rc5-lzzhzhcfg root=UUID=d0dbffd1-b19d-448b-8263-42049531bd8a ro quiet modprobe.blacklist=powervr cma=128M";
		boot-hartid = <0x02>;
		linux,uefi-mmap-start = <0x00 0xfe6de068>;
		linux,uefi-mmap-desc-size = <0x28>;
		linux,uefi-mmap-desc-ver = <0x01>;
		linux,uefi-system-table = <0x00 0xfff46fd0>;
		stdout-path = "serial0:115200n8";
	};

	gmac0_rgmii_rxin: gmac0-rgmii-rxin-clock {
		clock-output-names = "gmac0_rgmii_rxin";
		#clock-cells = <0x00>;
		clock-frequency = <0x7735940>;
		compatible = "fixed-clock";
		phandle = <0x35>;
	};

	cpus: cpus {
		#address-cells = <0x01>;
		#size-cells = <0x00>;
		timebase-frequency = "", "=\t";
		phandle = <0x4e>;

		U74_1: cpu@1 {
			i-tlb-sets = <0x01>;
			clock-names = "cpu";
			cpu-supply = <0x04>;
			clocks = <0x03 0x01>;
			d-cache-block-size = <0x40>;
			device_type = "cpu";
			compatible = "sifive,u74-mc", "riscv";
			mmu-type = "riscv,sv39";
			d-cache-size = <0x8000>;
			next-level-cache = <0x01>;
			riscv,isa-base = "rv64i";
			i-cache-size = <0x8000>;
			riscv,isa-extensions = "i", "m", "a", "f", "d", "c", "zba", "zbb", "zicntr", "zicsr", "zifencei", "zihpm";
			reg = <0x01>;
			phandle = <0x06>;
			d-cache-sets = <0x40>;
			i-cache-block-size = <0x40>;
			operating-points-v2 = <0x02>;
			i-cache-sets = <0x40>;
			d-tlb-size = <0x28>;
			riscv,isa = "rv64imafdc_zba_zbb";
			tlb-split;
			i-tlb-size = <0x28>;
			d-tlb-sets = <0x01>;
			#cooling-cells = <0x02>;

			cpu1_intc: interrupt-controller {
				compatible = "riscv,cpu-intc";
				#interrupt-cells = <0x01>;
				bootph-pre-ram;
				phandle = <0x0e>;
				interrupt-controller;
			};
		};

		U74_4: cpu@4 {
			i-tlb-sets = <0x01>;
			clock-names = "cpu";
			cpu-supply = <0x04>;
			clocks = <0x03 0x01>;
			d-cache-block-size = <0x40>;
			device_type = "cpu";
			compatible = "sifive,u74-mc", "riscv";
			mmu-type = "riscv,sv39";
			d-cache-size = <0x8000>;
			next-level-cache = <0x01>;
			riscv,isa-base = "rv64i";
			i-cache-size = <0x8000>;
			riscv,isa-extensions = "i", "m", "a", "f", "d", "c", "zba", "zbb", "zicntr", "zicsr", "zifencei", "zihpm";
			reg = <0x04>;
			phandle = <0x09>;
			d-cache-sets = <0x40>;
			i-cache-block-size = <0x40>;
			operating-points-v2 = <0x02>;
			i-cache-sets = <0x40>;
			d-tlb-size = <0x28>;
			riscv,isa = "rv64imafdc_zba_zbb";
			tlb-split;
			i-tlb-size = <0x28>;
			d-tlb-sets = <0x01>;
			#cooling-cells = <0x02>;

			cpu4_intc: interrupt-controller {
				compatible = "riscv,cpu-intc";
				#interrupt-cells = <0x01>;
				bootph-pre-ram;
				phandle = <0x11>;
				interrupt-controller;
			};
		};

		cpu-map {

			cluster0 {

				core3 {
					cpu = <0x08>;
				};

				core1 {
					cpu = <0x06>;
				};

				core4 {
					cpu = <0x09>;
				};

				core2 {
					cpu = <0x07>;
				};

				core0 {
					cpu = <0x05>;
				};
			};
		};

		U74_2: cpu@2 {
			i-tlb-sets = <0x01>;
			clock-names = "cpu";
			cpu-supply = <0x04>;
			clocks = <0x03 0x01>;
			d-cache-block-size = <0x40>;
			device_type = "cpu";
			compatible = "sifive,u74-mc", "riscv";
			mmu-type = "riscv,sv39";
			d-cache-size = <0x8000>;
			next-level-cache = <0x01>;
			riscv,isa-base = "rv64i";
			i-cache-size = <0x8000>;
			riscv,isa-extensions = "i", "m", "a", "f", "d", "c", "zba", "zbb", "zicntr", "zicsr", "zifencei", "zihpm";
			reg = <0x02>;
			phandle = <0x07>;
			d-cache-sets = <0x40>;
			i-cache-block-size = <0x40>;
			operating-points-v2 = <0x02>;
			i-cache-sets = <0x40>;
			d-tlb-size = <0x28>;
			riscv,isa = "rv64imafdc_zba_zbb";
			tlb-split;
			i-tlb-size = <0x28>;
			d-tlb-sets = <0x01>;
			#cooling-cells = <0x02>;

			cpu2_intc: interrupt-controller {
				compatible = "riscv,cpu-intc";
				#interrupt-cells = <0x01>;
				bootph-pre-ram;
				phandle = <0x0f>;
				interrupt-controller;
			};
		};

		S7_0: cpu@0 {
			device_type = "cpu";
			compatible = "sifive,s7", "riscv";
			status = "disabled";
			next-level-cache = <0x01>;
			riscv,isa-base = "rv64i";
			i-cache-size = <0x4000>;
			riscv,isa-extensions = "i", "m", "a", "c", "zba", "zbb", "zicntr", "zicsr", "zifencei", "zihpm";
			reg = <0x00>;
			phandle = <0x05>;
			i-cache-block-size = <0x40>;
			i-cache-sets = <0x40>;
			riscv,isa = "rv64imac_zba_zbb";

			cpu0_intc: interrupt-controller {
				compatible = "riscv,cpu-intc";
				#interrupt-cells = <0x01>;
				bootph-pre-ram;
				phandle = <0x0d>;
				interrupt-controller;
			};
		};

		U74_3: cpu@3 {
			i-tlb-sets = <0x01>;
			clock-names = "cpu";
			cpu-supply = <0x04>;
			clocks = <0x03 0x01>;
			d-cache-block-size = <0x40>;
			device_type = "cpu";
			compatible = "sifive,u74-mc", "riscv";
			mmu-type = "riscv,sv39";
			d-cache-size = <0x8000>;
			next-level-cache = <0x01>;
			riscv,isa-base = "rv64i";
			i-cache-size = <0x8000>;
			riscv,isa-extensions = "i", "m", "a", "f", "d", "c", "zba", "zbb", "zicntr", "zicsr", "zifencei", "zihpm";
			reg = <0x03>;
			phandle = <0x08>;
			d-cache-sets = <0x40>;
			i-cache-block-size = <0x40>;
			operating-points-v2 = <0x02>;
			i-cache-sets = <0x40>;
			d-tlb-size = <0x28>;
			riscv,isa = "rv64imafdc_zba_zbb";
			tlb-split;
			i-tlb-size = <0x28>;
			d-tlb-sets = <0x01>;
			#cooling-cells = <0x02>;

			cpu3_intc: interrupt-controller {
				compatible = "riscv,cpu-intc";
				#interrupt-cells = <0x01>;
				bootph-pre-ram;
				phandle = <0x10>;
				interrupt-controller;
			};
		};
	};

	__symbols__ {
		i2c3 = "/soc/i2c@12030000";
		pwm = "/soc/pwm@120d0000";
		i2stx1 = "/soc/i2s@120c0000";
		i2srx = "/soc/i2s@100e0000";
		sys_syscon = "/soc/syscon@13030000";
		U74_1 = "/cpus/cpu@1";
		clint = "/soc/timer@2000000";
		aongpio = "/soc/pinctrl@17020000";
		cpu_opp = "/opp-table-0";
		ispcrg = "/soc/clock-controller@19810000";
		spi2 = "/soc/spi@10080000";
		crypto = "/soc/crypto@16000000";
		axp15060 = "/soc/i2c@12050000/pmic@36";
		stg_syscon = "/soc/syscon@10240000";
		i2c1 = "/soc/i2c@10040000";
		hdmi_subsystem = "/soc/display-subsystem@29400000/hdmi@29590000";
		pciephy0 = "/soc/phy@10210000";
		osc = "/oscillator";
		gmac0 = "/soc/ethernet@16030000";
		cpu1_intc = "/cpus/cpu@1/interrupt-controller";
		hdmi_con_in = "/hdmi-connector/port/endpoint";
		mclk_ext = "/mclk-ext-clock";
		qspi = "/soc/spi@13010000";
		ccache = "/soc/cache-controller@2010000";
		nor_flash = "/soc/spi@13010000/flash@0";
		gpu = "/soc/gpu@18000000";
		spi0 = "/soc/spi@10060000";
		sfctemp = "/soc/temperature-sensor@120e0000";
		hdmi_controller = "/soc/display-subsystem@29400000/hdmi@29590000/controller";
		syscrg = "/soc/clock-controller@13020000";
		pwmdac_codec = "/audio-codec";
		mmc1 = "/soc/mmc@16020000";
		aoncrg = "/soc/clock-controller@17000000";
		hdmi_phy = "/soc/display-subsystem@29400000/hdmi@29590000/phy";
		csi2rx = "/soc/csi@19800000";
		stmmac_axi_setup = "/stmmac-axi-config";
		uart4 = "/soc/serial@12010000";
		stgcrg = "/soc/clock-controller@10230000";
		sdma = "/soc/dma-controller@16008000";
		phy1 = "/soc/ethernet@16040000/mdio/ethernet-phy@1";
		cpu_alert0 = "/thermal-zones/cpu-thermal/trips/cpu-alert0";
		aon_syscon = "/soc/syscon@17010000";
		dma = "/soc/dma-controller@16050000";
		cpu0_intc = "/cpus/cpu@0/interrupt-controller";
		led_status_power = "/leds/led-0";
		dc8200 = "/soc/display-subsystem@29400000/display@29400000";
		pcie_intc0 = "/soc/pcie@940000000/interrupt-controller";
		uart2 = "/soc/serial@10020000";
		vout_subsystem = "/soc/display-subsystem@29400000";
		sndcpu0 = "/sound/simple-audio-card,dai-link@0/cpu";
		i2c6 = "/soc/i2c@12060000";
		pcie0 = "/soc/pcie@940000000";
		pwmdac = "/soc/pwmdac@100b0000";
		emmc_vdd = "/soc/i2c@12050000/pmic@36/regulators/aldo4";
		U74_4 = "/cpus/cpu@4";
		gmac0_rmii_refin = "/gmac0-rmii-refin-clock";
		mmc1_pins = "/soc/pinctrl@13040000/mmc1-0";
		xin24m = "/xin24m-clock";
		spi5 = "/soc/spi@12090000";
		uart0 = "/soc/serial@10000000";
		i2c2_pins = "/soc/pinctrl@13040000/i2c2-0";
		dpu_out_dpi0 = "/soc/display-subsystem@29400000/display@29400000/ports/port@0/endpoint@0";
		i2c4 = "/soc/i2c@12040000";
		vdd_cpu = "/soc/i2c@12050000/pmic@36/regulators/dcdc2";
		pllclk = "/soc/syscon@13030000/clock-controller";
		U74_2 = "/cpus/cpu@2";
		rng = "/soc/rng@1600c000";
		pwrc = "/soc/power-controller@17030000";
		rtc_osc = "/rtc-oscillator";
		spi3 = "/soc/spi@12070000";
		gmac0_rgmii_rxin = "/gmac0-rgmii-rxin-clock";
		dpu_port0 = "/soc/display-subsystem@29400000/display@29400000/ports/port@0";
		i2c2 = "/soc/i2c@10050000";
		pciephy1 = "/soc/phy@10220000";
		S7_0 = "/cpus/cpu@0";
		i2stx0 = "/soc/i2s@120b0000";
		mmc0_pins = "/soc/pinctrl@13040000/mmc0-0";
		gmac1 = "/soc/ethernet@16040000";
		hdmi_out_port = "/soc/display-subsystem@29400000/hdmi@29590000/controller/ports/port@1";
		pwmdac_pins = "/soc/pinctrl@13040000/pwmdac-0";
		i2stx_bclk_ext = "/i2stx-bclk-ext-clock";
		spi1 = "/soc/spi@10070000";
		hdmi_out_con = "/soc/display-subsystem@29400000/hdmi@29590000/controller/ports/port@1/endpoint";
		usbphy0 = "/soc/phy@10200000";
		i2stx_lrck_ext = "/i2stx-lrck-ext-clock";
		i2c0 = "/soc/i2c@10030000";
		hdmi_pins = "/soc/pinctrl@13040000/hdmi-0";
		cpu4_intc = "/cpus/cpu@4/interrupt-controller";
		voutcrg = "/soc/display-subsystem@29400000/clock-controller@295c0000";
		uart5 = "/soc/serial@12020000";
		dvp_clk = "/dvp-clock";
		mmc0 = "/soc/mmc@16010000";
		usb0 = "/soc/usb@10100000";
		i2c0_pins = "/soc/pinctrl@13040000/i2c0-0";
		vout_syscon = "/soc/display-subsystem@29400000/syscon@295b0000";
		pcie1_pins = "/soc/pinctrl@13040000/pcie1-0";
		pcie_intc1 = "/soc/pcie@9c0000000/interrupt-controller";
		uart3 = "/soc/serial@12000000";
		usb_cdns3 = "/soc/usb@10100000/usb@0";
		i2srx_bclk_ext = "/i2srx-bclk-ext-clock";
		csi_phy = "/soc/phy@19820000";
		phy0 = "/soc/ethernet@16030000/mdio/ethernet-phy@0";
		gmac1_rmii_refin = "/gmac1-rmii-refin-clock";
		spi0_pins = "/soc/pinctrl@13040000/spi0-0";
		cpu3_intc = "/cpus/cpu@3/interrupt-controller";
		i2c6_pins = "/soc/pinctrl@13040000/i2c6-0";
		pcie1 = "/soc/pcie@9c0000000";
		i2srx_lrck_ext = "/i2srx-lrck-ext-clock";
		plic = "/soc/interrupt-controller@c000000";
		spi6 = "/soc/spi@120a0000";
		cpus = "/cpus";
		pwm_pins = "/soc/pinctrl@13040000/pwm-0";
		tdm = "/soc/tdm@10090000";
		uart1 = "/soc/serial@10010000";
		hdmi_in = "/soc/display-subsystem@29400000/hdmi@29590000/controller/ports/port@0/endpoint";
		i2c5 = "/soc/i2c@12050000";
		sysgpio = "/soc/pinctrl@13040000";
		pcie0_pins = "/soc/pinctrl@13040000/pcie0-0";
		gmac1_rgmii_rxin = "/gmac1-rgmii-rxin-clock";
		U74_3 = "/cpus/cpu@3";
		vcc_3v3 = "/soc/i2c@12050000/pmic@36/regulators/dcdc1";
		tdm_ext = "/tdm-ext-clock";
		spi4 = "/soc/spi@12080000";
		uart0_pins = "/soc/pinctrl@13040000/uart0-0";
		cpu2_intc = "/cpus/cpu@2/interrupt-controller";
		i2c5_pins = "/soc/pinctrl@13040000/i2c5-0";
		dpu_port1 = "/soc/display-subsystem@29400000/display@29400000/ports/port@1";
	};

	reserved-memory {
		#address-cells = <0x02>;
		#size-cells = <0x02>;
		ranges;

		linux,cma {
			linux,cma-default;
			alignment = <0x00 0x1000>;
			alloc-ranges = <0x00 0x70000000 0x00 0x20000000>;
			compatible = "shared-dma-pool";
			size = <0x00 0x20000000>;
			reusable;
		};

		mmode_resv0@40040000 {
			reg = <0x00 0x40040000 0x00 0x20000>;
			phandle = <0x81>;
			no-map;
		};

		mmode_resv1@40000000 {
			reg = <0x00 0x40000000 0x00 0x40000>;
			phandle = <0x80>;
			no-map;
		};
	};

	pwmdac_codec: audio-codec {
		#sound-dai-cells = <0x00>;
		compatible = "linux,spdif-dit";
		phandle = <0x4c>;
	};

	i2srx_bclk_ext: i2srx-bclk-ext-clock {
		clock-output-names = "i2srx_bclk_ext";
		#clock-cells = <0x00>;
		clock-frequency = <0xbb8000>;
		compatible = "fixed-clock";
		phandle = <0x19>;
	};

	hdmi-connector {
		type = "a";
		compatible = "hdmi-connector";

		port {

			hdmi_con_in: endpoint {
				remote-endpoint = <0x4d>;
				phandle = <0x41>;
			};
		};
	};
};
